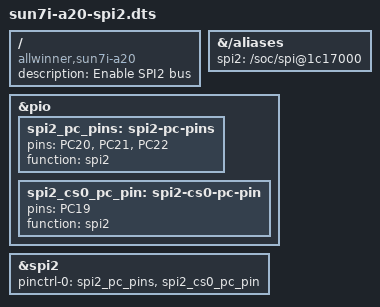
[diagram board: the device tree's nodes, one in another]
/dts-v1/;
/plugin/;

/ {
	compatible = "allwinner,sun7i-a20";
	description = "Enable SPI2 bus";

	fragment@0 {
		target-path = "/aliases";
		__overlay__ {
			spi2 = "/soc/spi@1c17000";
		};
	};

	fragment@1 {
		target = <&pio>;
		__overlay__ {
			spi2_pc_pins: spi2-pc-pins {
				pins = "PC20", "PC21", "PC22";
				function = "spi2";
			};

			spi2_cs0_pc_pin: spi2-cs0-pc-pin {
				pins = "PC19";
				function = "spi2";
			};
		};
	};

	fragment@2 {
		target = <&spi2>;
		__overlay__ {
			pinctrl-names = "default";
			pinctrl-0 = <&spi2_pc_pins>, <&spi2_cs0_pc_pin>;
			status = "okay";
		};
	};
};
